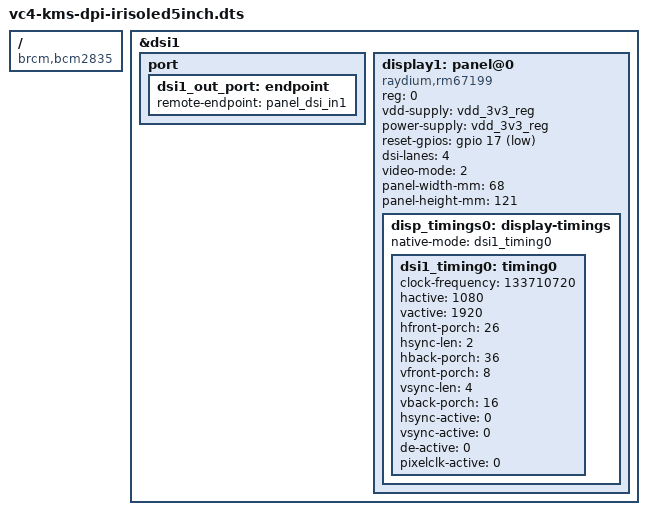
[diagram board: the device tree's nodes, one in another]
/dts-v1/;
/plugin/;

#include <dt-bindings/gpio/gpio.h>


/ {

  compatible = "brcm,bcm2835";

  fragment@0 {
    target=<&dsi1>;

    __overlay__ {
      status = "okay";
      #address-cells = <1>;
      #size-cells = <0>;

      port {
          dsi1_out_port: endpoint {
              remote-endpoint = <&panel_dsi_in1>;
          };
      };

      display1: panel@0 {
        compatible = "raydium,rm67199";
        reg=<0>;

        vdd-supply = <&vdd_3v3_reg>;
        power-supply = <&vdd_3v3_reg>;
        reset-gpios =  <&gpio 17 1>;
        dsi-lanes = <4>;
        video-mode = <2>;
        panel-width-mm = <68>;
        panel-height-mm = <121>;

        disp_timings0: display-timings {
          native-mode = <&dsi1_timing0>;
          dsi1_timing0: timing0 {
            clock-frequency = <133710720>;
            hactive = <1080>;
            vactive = <1920>;
            hfront-porch = <26>;
            hsync-len = <2>;
            hback-porch = <36>;
            vfront-porch = <8>;
            vsync-len = <4>;
            vback-porch = <16>;
            hsync-active = <0>;
            vsync-active = <0>;
            de-active = <0>;
            pixelclk-active = <0>;
          };
        };
      };
    };
  };

  
  };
